# STM32F767xx register map
File version: 1.0
Registers are 32-bit, read-write, reset 0x0 unless marked. A register's access mark holds for its fields unless they carry their own. Offsets are from the block's base; [hi:lo] are bit positions; {n}, {i} and the like mark numbered series.

## MDIOS
Base 0x40017800
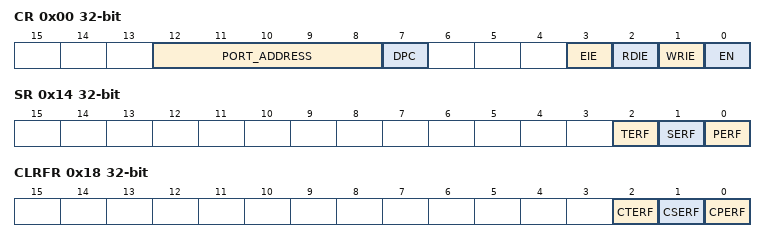
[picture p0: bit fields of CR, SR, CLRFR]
0x00 CR — MDIOS Configuration Register (MDIOS_CR)
  [12:8] PORT_ADDRESS — PORT_ADDRESS[4:0] bits
  [7] DPC — Disable Preamble Check
  [3] EIE — Error interrupt enable
  [2] RDIE — Register Read Interrupt Enable
  [1] WRIE — Register write interrupt enable
  [0] EN — Peripheral enable
0x04 WRFR — MDIOS Configuration Register (MDIOS_CR)
  [31:0] WRF — WRF[31:0] bits (Write flags for MDIO register 0 to 31)
0x08 CWRFR — MDIOS Configuration Register (MDIOS_CR)
  [31:0] CWRF — CWRF[31:0] bits (Clear the write flag for MDIO register 0 to 31)
0x0C RDFR — MDIOS Configuration Register (MDIOS_CR)
  [31:0] RDF — RDF[31:0] bits (Read flags for MDIO registers 0 to 31)
0x10 CRDFR — MDIOS Configuration Register (MDIOS_CR)
  [31:0] CRDF — CRDF[31:0] bits (Clear the read flag for MDIO registers 0 to 31)
0x14 SR — MDIOS Configuration Register (MDIOS_CR)
  [2] TERF — Turnaround error flag
  [1] SERF — Start error flag
  [0] PERF — Preamble error flag
0x18 CLRFR — MDIOS Configuration Register (MDIOS_CR)
  [2] CTERF — Clear the turnaround error flag
  [1] CSERF — Clear the start error flag
  [0] CPERF — Clear the preamble error flag
{0x100+4i} DINR{i} (i=0..31) — MDIOS Input Data Register (MDIOS_DINR{i})
{0x180+4i} DOUTR{i} (i=0..31) — MDIOS Output Data Register (MDIOS_DOUTR{i})

## GPIOA — General Purpose I/O
Base 0x40020000
Same registers: GPIOB 0x40020400, GPIOC 0x40020800, GPIOD 0x40020C00, GPIOE 0x40021000, GPIOF 0x40021400, GPIOG 0x40021800, GPIOH 0x40021C00, GPIOI 0x40022000, GPIOJ 0x40022400, GPIOK 0x40022800
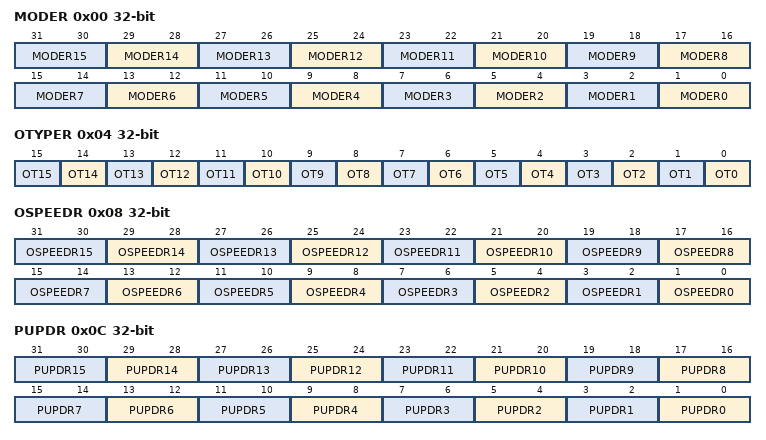
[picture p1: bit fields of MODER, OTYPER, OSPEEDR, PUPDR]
0x00 MODER — GPIO port mode register
  [2n+1:2n] MODER{n} (n=0..15)
0x04 OTYPER — GPIO port output type register
  [n] OT{n} (n=0..15)
0x08 OSPEEDR — GPIO port output speed register
  [2n+1:2n] OSPEEDR{n} (n=0..15)
0x0C PUPDR — GPIO port pull-up/pull-down register
  [2n+1:2n] PUPDR{n} (n=0..15)
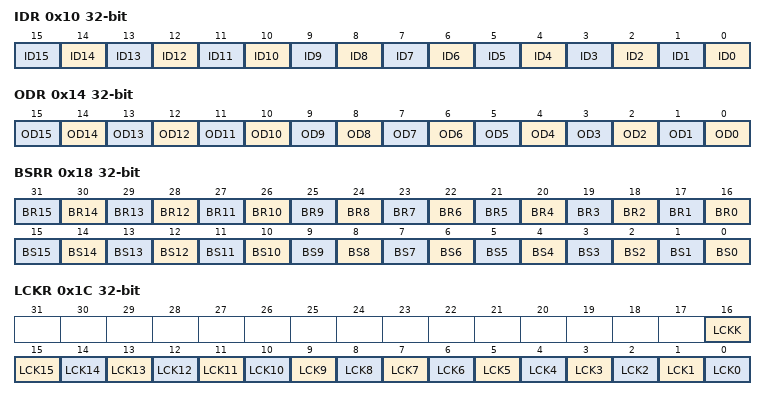
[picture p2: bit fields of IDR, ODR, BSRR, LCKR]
0x10 IDR — GPIO port input data register
  [n] ID{n} (n=0..15)
0x14 ODR — GPIO port output data register
  [n] OD{n} (n=0..15)
0x18 BSRR — GPIO port bit set/reset register
  [n+16] BR{n} (n=0..15), [n] BS{n} (n=0..15)
0x1C LCKR — GPIO port configuration lock register
  [16] LCKK, [n] LCK{n} (n=0..15)
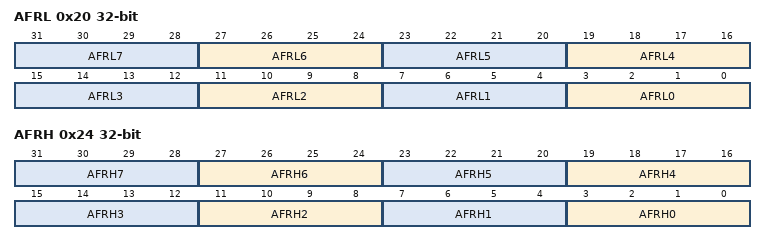
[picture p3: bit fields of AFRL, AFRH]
0x20 AFRL — GPIO alternate function registers
  [4n+3:4n] AFRL{n} (n=0..7)
0x24 AFRH — GPIO alternate function registers
  [4n+3:4n] AFRH{n} (n=0..7)

## CRC — CRC calculation unit
Base 0x40023000
0x00 DR — CRC Data register
  [31:0] DR — Data register bits
0x04 IDR 8-bit — CRC Independent data register
  [7:0] IDR — General-purpose 8-bit data register bits
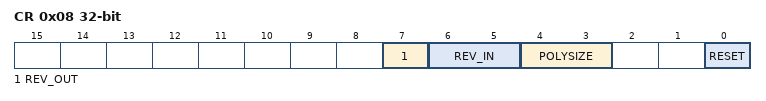
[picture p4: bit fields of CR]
0x08 CR — CRC Control register
  [7] REV_OUT — REV_OUT Reverse Output Data bits
    0=NONE (Output Data bit order not affected); 1=BIT (Output Data bit reversal done by bit)
  [6:5] REV_IN — REV_IN Reverse Input Data bits
    0=NONE (Input Data bit order not affected); 1=BYTE (Input Data bit reversal done by byte); 2=HALFWORD (Input Data bit reversal done by half-word); 3=WORD (Input Data bit reversal done by word)
  [4:3] POLYSIZE — Polynomial size bits
    0=POLYLENGTH_32B (32 bits Polynomial size); 1=POLYLENGTH_16B (16 bits Polynomial size); 2=POLYLENGTH_8B (8 bits Polynomial size); 3=POLYLENGTH_7B (7 bits Polynomial size)
  [0] RESET — RESET the CRC computation unit bit
0x10 INIT — Initial CRC value register
  [31:0] INIT — Initial CRC value bits
0x14 POL — CRC polynomial register
  [31:0] POL — Coefficients of the polynomial

## FLASH — FLASH Registers
Base 0x40023C00
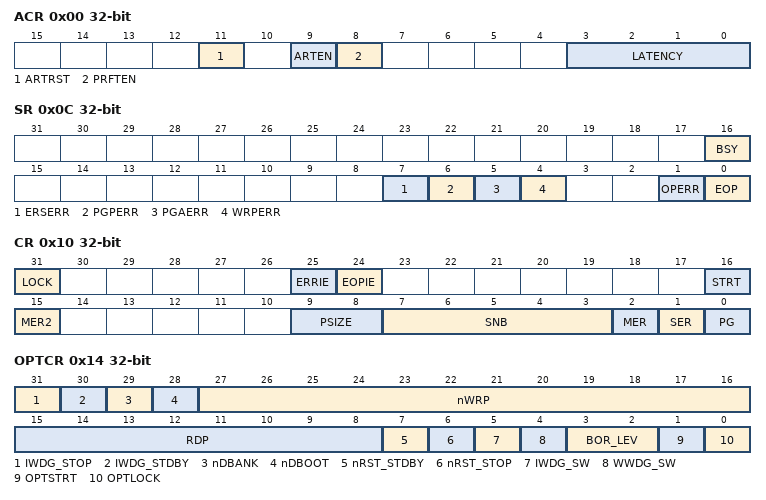
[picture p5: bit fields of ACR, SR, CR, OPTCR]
0x00 ACR — FLASH access control register
  [11] ARTRST
  [9] ARTEN
  [8] PRFTEN
  [3:0] LATENCY
    0=FLASH Zero wait state; 1=FLASH One wait state; 2=FLASH Two wait states; 3=FLASH Three wait states; 4=FLASH Four wait states; 5=FLASH five wait state; 6=FLASH six wait state; 7=FLASH seven wait states; 8=FLASH eight wait states; 9=FLASH nine wait states; 10=FLASH ten wait states; 11=FLASH eleven wait states; 12=FLASH twelve wait states; 13=FLASH thirteen wait states; 14=FLASH fourteen wait states; 15=FLASH fifteen wait states
0x04 KEYR — FLASH key register
0x08 OPTKEYR — FLASH option key register
0x0C SR — FLASH status register
  [16] BSY, [7] ERSERR, [6] PGPERR, [5] PGAERR, [4] WRPERR, [1] OPERR, [0] EOP
0x10 CR — FLASH control register
  [31] LOCK, [25] ERRIE, [24] EOPIE, [16] STRT, [15] MER2, [9:8] PSIZE, [7:3] SNB, [2] MER, [1] SER, [0] PG
0x14 OPTCR — FLASH option control register
  [31] IWDG_STOP, [30] IWDG_STDBY, [29] nDBANK, [28] nDBOOT, [27:16] nWRP, [15:8] RDP, [7] nRST_STDBY, [6] nRST_STOP, [5] IWDG_SW, [4] WWDG_SW, [3:2] BOR_LEV, [1] OPTSTRT, [0] OPTLOCK
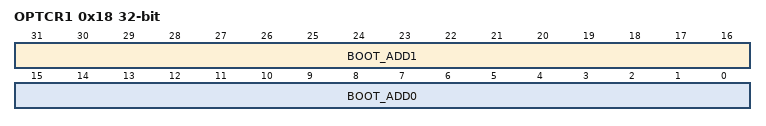
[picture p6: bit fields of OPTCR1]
0x18 OPTCR1 — FLASH option control register 1
  [31:16] BOOT_ADD1, [15:0] BOOT_ADD0
